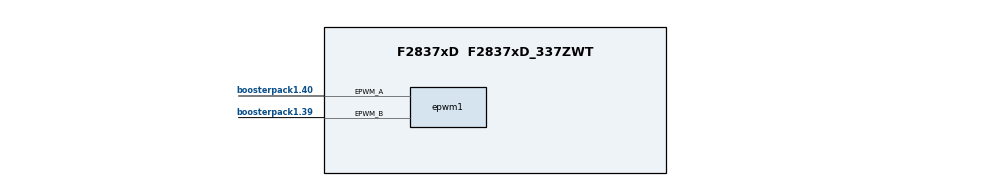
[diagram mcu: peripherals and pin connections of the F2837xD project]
/**
 * @cliArgs --board "/boards/LAUNCHXL_F28379D" --device "F2837xD" --part "F2837xD_337ZWT" --package "F2837xD_337ZWT" --context "CPU1" --product "C2000WARE@5.04.00.00"
 * @versions {"tool":"1.23.0+4000"}
 */

/**
 * Import the modules used in this configuration.
 */
const adc   = scripting.addModule("/driverlib/adc.js", {}, false);
const adc1  = adc.addInstance();
const epwm  = scripting.addModule("/driverlib/epwm.js", {}, false);
const epwm1 = epwm.addInstance();
const gpio  = scripting.addModule("/driverlib/gpio.js", {}, false);
const gpio1 = gpio.addInstance();

/**
 * Write custom configuration values to the imported modules.
 */
adc1.$name                   = "ADC_Sine";
adc1.enabledSOCs             = ["ADC_SOC_NUMBER0"];
adc1.soc0Trigger             = "ADC_TRIGGER_EPWM1_SOCA";
adc1.adcClockPrescaler       = "ADC_CLK_DIV_4_0";
adc1.soc0InterruptTrigger    = "ADC_INT_SOC_TRIGGER_ADCINT1";
adc1.enabledInts             = ["ADC_INT_NUMBER1"];
adc1.enableInterrupt1        = true;
adc1.registerInterrupts      = ["1"];
adc1.socHighPriorityMode     = "ADC_PRI_SOC0_HIPRI";
adc1.interruptPulseMode      = "ADC_PULSE_END_OF_CONV";
adc1.soc0Channel             = "ADC_CH_ADCIN13";
adc1.soc0SampleWindow        = 140;
adc1.adcInt1.enableInterrupt = true;

epwm1.$name                                                      = "Pwm_FPB";
epwm1.epwmActionQualifier_EPWM_AQ_OUTPUT_A_ON_TIMEBASE_UP_CMPA   = "EPWM_AQ_OUTPUT_HIGH";
epwm1.epwmActionQualifier_EPWM_AQ_OUTPUT_A_ON_TIMEBASE_DOWN_CMPA = "EPWM_AQ_OUTPUT_LOW";
epwm1.epwmTimebase_counterMode                                   = "EPWM_COUNTER_MODE_UP_DOWN";
epwm1.epwmTimebase_counterModeAfterSync                          = "EPWM_COUNT_MODE_UP_AFTER_SYNC";
epwm1.epwmTimebase_emulationMode                                 = "EPWM_EMULATION_FREE_RUN";
epwm1.epwmTimebase_period                                        = 2500;
epwm1.epwmCounterCompare_cmpA                                    = 1250;
epwm1.epwmTimebase_hsClockDiv                                    = "EPWM_HSCLOCK_DIVIDER_1";
epwm1.epwmActionQualifier_EPWM_AQ_OUTPUT_B_ON_TIMEBASE_UP_CMPB   = "EPWM_AQ_OUTPUT_HIGH";
epwm1.epwmActionQualifier_EPWM_AQ_OUTPUT_B_ON_TIMEBASE_DOWN_CMPB = "EPWM_AQ_OUTPUT_LOW";
epwm1.epwmCounterCompare_cmpB                                    = 1250;
epwm1.epwmEventTrigger_EPWM_SOC_A_triggerEnable                  = true;
epwm1.epwmEventTrigger_EPWM_SOC_A_triggerSource                  = "EPWM_SOC_TBCTR_U_CMPA";
epwm1.epwmEventTrigger_enableInterrupt                           = true;
epwm1.epwmEventTrigger_interruptSource                           = "EPWM_INT_TBCTR_U_CMPA";
epwm1.epwm.$assign                                               = "EPWM1";
epwm1.epwm.epwm_aPin.$assign                                     = "boosterpack1.40";
epwm1.epwm.epwm_bPin.$assign                                     = "boosterpack1.39";
scripting.suppress("Connected to hardware,@@@.+?@@@ is connected to EPWM1 BP on the LaunchPad F28379D\\. Consider selecting it in \'use hardware\' above\\. @@@.+?@@@", epwm1.epwm, "epwm_aPin");
scripting.suppress("Connected to hardware,@@@.+?@@@ is connected to EPWM1 BP on the LaunchPad F28379D\\. Consider selecting it in \'use hardware\' above\\. @@@.+?@@@", epwm1.epwm, "epwm_bPin");

gpio1.$name     = "Led_Blink";
gpio1.$hardware = system.deviceData.board.components.LED4;
gpio1.direction = "GPIO_DIR_MODE_OUT";

/**
 * Pinmux solution for unlocked pins/peripherals. This ensures that minor changes to the automatic solver in a future
 * version of the tool will not impact the pinmux you originally saw.  These lines can be completely deleted in order to
 * re-solve from scratch.
 */
gpio1.gpioPin.$suggestSolution = "GPIO31";
